# AM13E230x register map
Vendor: Texas Instruments; File version: Revised: 2025-12-26 17:30:06
CPU: CM33 r0p0, little endian, MPU, FPU, 4 interrupt priority bits
Registers are 32-bit, read-write, reset 0x0 unless marked. A register's access mark holds for its fields unless they carry their own. Offsets are from the block's base; [hi:lo] are bit positions; {n}, {i} and the like mark numbered series.

## INPUTXBAR_FLAGS — INPUT_FLAG_XBAR_REGS
Base 0x40490000
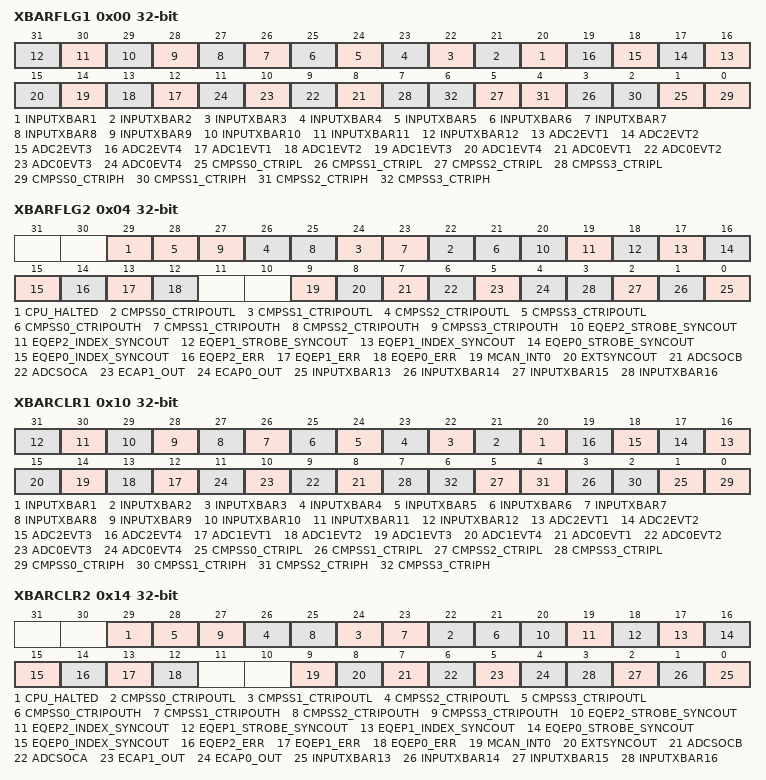
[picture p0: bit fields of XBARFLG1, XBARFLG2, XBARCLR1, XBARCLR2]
0x00 XBARFLG1 — X-Bar Input Flag Register 1
  [n+19] INPUTXBAR{n} ro (n=1..12) — Input Flag for INPUTXBAR{n} Signal
  [n+15] ADC2EVT{n} ro (n=1..4) — Input Flag for ADC2EVT{n} Signal
  [n+11] ADC1EVT{n} ro (n=1..4) — Input Flag for ADC1EVT{n} Signal
  [n+7] ADC0EVT{n} ro (n=1..4) — Input Flag for ADC0EVT{n} Signal
  [2n+1] CMPSS{n}_CTRIPL ro (n=0..3) — Input Flag for CMPSS{n}_CTRIPL Signal
  [2n] CMPSS{n}_CTRIPH ro (n=0..3) — Input Flag for CMPSS{n}_CTRIPH Signal
0x04 XBARFLG2 — X-Bar Input Flag Register 2
  [29] CPU_HALTED ro — Input Flag for CPU_HALTED Signal
  [2n+22] CMPSS{n}_CTRIPOUTL ro (n=0..3) — Input Flag for CMPSS{n}_CTRIPOUTL Signal
  [2n+21] CMPSS{n}_CTRIPOUTH ro (n=0..3) — Input Flag for CMPSS{n}_CTRIPOUTH Signal
  [20] EQEP2_STROBE_SYNCOUT ro — Input Flag for EQEP2_STROBE_SYNCOUT Signal
  [19] EQEP2_INDEX_SYNCOUT ro — Input Flag for EQEP2_INDEX_SYNCOUT Signal
  [18] EQEP1_STROBE_SYNCOUT ro — Input Flag for EQEP1_STROBE_SYNCOUT Signal
  [17] EQEP1_INDEX_SYNCOUT ro — Input Flag for EQEP1_INDEX_SYNCOUT Signal
  [16] EQEP0_STROBE_SYNCOUT ro — Input Flag for EQEP0_STROBE_SYNCOUT Signal
  [15] EQEP0_INDEX_SYNCOUT ro — Input Flag for EQEP0_INDEX_SYNCOUT Signal
  [14] EQEP2_ERR ro — Input Flag for EQEP2_ERR Signal
  [13] EQEP1_ERR ro — Input Flag for EQEP1_ERR Signal
  [12] EQEP0_ERR ro — Input Flag for EQEP0_ERR Signal
  [9] MCAN_INT0 ro — Input Flag for MCAN_INT0 Signal
  [8] EXTSYNCOUT ro — Input Flag for EXTSYNCOUT Signal
  [7] ADCSOCB ro — Input Flag for ADCSOCB Signal
  [6] ADCSOCA ro — Input Flag for ADCSOCA Signal
  [5] ECAP1_OUT ro — Input Flag for ECAP1_OUT Signal
  [4] ECAP0_OUT ro — Input Flag for ECAP0_OUT Signal
  [n-13] INPUTXBAR{n} ro (n=13..16) — Input Flag for INPUTXBAR{n} Signal
0x10 XBARCLR1 — X-Bar Input Flag Clear Register 1
  [n+19] INPUTXBAR{n} (n=1..12) — Input Flag Clear for INPUTXBAR{n} Signal
  [n+15] ADC2EVT{n} (n=1..4) — Input Flag Clear for ADC2EVT{n} Signal
  [n+11] ADC1EVT{n} (n=1..4) — Input Flag Clear for ADC1EVT{n} Signal
  [n+7] ADC0EVT{n} (n=1..4) — Input Flag Clear for ADC0EVT{n} Signal
  [2n+1] CMPSS{n}_CTRIPL (n=0..3) — Input Flag Clear for CMPSS{n}_CTRIPL Signal
  [2n] CMPSS{n}_CTRIPH (n=0..3) — Input Flag Clear for CMPSS{n}_CTRIPH Signal
0x14 XBARCLR2 — X-Bar Input Flag Clear Register 2
  [29] CPU_HALTED — Input Flag Clear for CPU_HALTED Signal
  [2n+22] CMPSS{n}_CTRIPOUTL (n=0..3) — Input Flag Clear for CMPSS{n}_CTRIPOUTL Signal
  [2n+21] CMPSS{n}_CTRIPOUTH (n=0..3) — Input Flag Clear for CMPSS{n}_CTRIPOUTH Signal
  [20] EQEP2_STROBE_SYNCOUT — Input Flag Clear for EQEP2_STROBE_SYNCOUT Signal
  [19] EQEP2_INDEX_SYNCOUT — Input Flag Clear for EQEP2_INDEX_SYNCOUT Signal
  [18] EQEP1_STROBE_SYNCOUT — Input Flag Clear for EQEP1_STROBE_SYNCOUT Signal
  [17] EQEP1_INDEX_SYNCOUT — Input Flag Clear for EQEP1_INDEX_SYNCOUT Signal
  [16] EQEP0_STROBE_SYNCOUT — Input Flag Clear for EQEP0_STROBE_SYNCOUT Signal
  [15] EQEP0_INDEX_SYNCOUT — Input Flag Clear for EQEP0_INDEX_SYNCOUT Signal
  [14] EQEP2_ERR — Input Flag Clear for EQEP2_ERR Signal
  [13] EQEP1_ERR — Input Flag Clear for EQEP1_ERR Signal
  [12] EQEP0_ERR — Input Flag Clear for EQEP0_ERR Signal
  [9] MCAN_INT0 — Input Flag Clear for MCAN_INT0 Signal
  [8] EXTSYNCOUT — Input Flag Clear for EXTSYNCOUT Signal
  [7] ADCSOCB — Input Flag Clear for ADCSOCB Signal
  [6] ADCSOCA — Input Flag Clear for ADCSOCA Signal
  [5] ECAP1_OUT — Input Flag Clear for ECAP1_OUT Signal
  [4] ECAP0_OUT — Input Flag Clear for ECAP0_OUT Signal
  [n-13] INPUTXBAR{n} (n=13..16) — Input Flag Clear for INPUTXBAR{n} Signal
